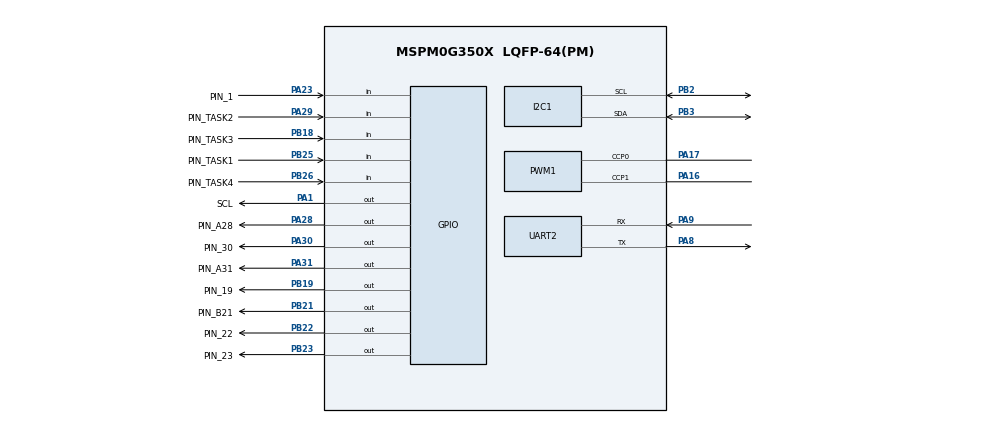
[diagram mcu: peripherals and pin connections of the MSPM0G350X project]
/**
 * @cliArgs --device "MSPM0G350X" --part "Default" --package "LQFP-64(PM)" --product "mspm0_sdk@2.05.01.00"
 * @versions {"tool":"1.24.0+4150"}
 */

/**
 * Import the modules used in this configuration.
 */
const GPIO    = scripting.addModule("/ti/driverlib/GPIO", {}, false);
const GPIO1   = GPIO.addInstance();
const GPIO2   = GPIO.addInstance();
const GPIO3   = GPIO.addInstance();
const GPIO4   = GPIO.addInstance();
const GPIO5   = GPIO.addInstance();
const GPIO6   = GPIO.addInstance();
const GPIO7   = GPIO.addInstance();
const GPIO8   = GPIO.addInstance();
const I2C     = scripting.addModule("/ti/driverlib/I2C", {}, false);
const I2C1    = I2C.addInstance();
const PWM     = scripting.addModule("/ti/driverlib/PWM", {}, false);
const PWM1    = PWM.addInstance();
const SYSCTL  = scripting.addModule("/ti/driverlib/SYSCTL");
const SYSTICK = scripting.addModule("/ti/driverlib/SYSTICK");
const TIMER   = scripting.addModule("/ti/driverlib/TIMER", {}, false);
const TIMER1  = TIMER.addInstance();
const TIMER2  = TIMER.addInstance();
const UART    = scripting.addModule("/ti/driverlib/UART", {}, false);
const UART1   = UART.addInstance();
const UART2   = UART.addInstance();
const UART3   = UART.addInstance();

/**
 * Write custom configuration values to the imported modules.
 */
const gate7  = system.clockTree["MFCLKGATE"];
gate7.enable = true;

GPIO1.$name                   = "GPIO_GRP_0";
GPIO1.associatedPins[0].$name = "PIN_0";

const Board = scripting.addModule("/ti/driverlib/Board", {}, false);

GPIO2.$name                   = "OLED";
GPIO2.associatedPins.create(3);
GPIO2.associatedPins[0].$name = "RES";
GPIO2.associatedPins[1].$name = "DC";
GPIO2.associatedPins[2].$name = "CS";

GPIO3.$name                               = "GPIO_ENCODER";
GPIO3.port                                = "PORTA";
GPIO3.associatedPins.create(2);
GPIO3.associatedPins[0].$name             = "PIN_LA";
GPIO3.associatedPins[0].direction         = "INPUT";
GPIO3.associatedPins[0].interruptEn       = true;
GPIO3.associatedPins[0].polarity          = "RISE";
GPIO3.associatedPins[0].assignedPin       = "26";
GPIO3.associatedPins[0].interruptPriority = "1";
GPIO3.associatedPins[1].direction         = "INPUT";
GPIO3.associatedPins[1].interruptEn       = true;
GPIO3.associatedPins[1].polarity          = "RISE";
GPIO3.associatedPins[1].assignedPin       = "27";
GPIO3.associatedPins[1].$name             = "PIN_LB";
GPIO3.associatedPins[1].interruptPriority = "1";

GPIO4.$name                          = "GPIO_MOTOR";
GPIO4.port                           = "PORTA";
GPIO4.associatedPins.create(4);
GPIO4.associatedPins[0].assignedPin  = "14";
GPIO4.associatedPins[0].$name        = "PIN_A14";
GPIO4.associatedPins[1].initialValue = "SET";
GPIO4.associatedPins[1].assignedPin  = "15";
GPIO4.associatedPins[1].$name        = "PIN_A15";
GPIO4.associatedPins[2].initialValue = "SET";
GPIO4.associatedPins[2].$name        = "PIN_A28";
GPIO4.associatedPins[2].assignedPin  = "28";
GPIO4.associatedPins[2].pin.$assign  = "PA28";
GPIO4.associatedPins[3].$name        = "PIN_A31";
GPIO4.associatedPins[3].assignedPin  = "31";
GPIO4.associatedPins[3].pin.$assign  = "PA31";

GPIO5.$name                               = "GPIO_BUTTON";
GPIO5.associatedPins.create(4);
GPIO5.associatedPins[0].direction         = "INPUT";
GPIO5.associatedPins[0].internalResistor  = "PULL_UP";
GPIO5.associatedPins[0].assignedPin       = "25";
GPIO5.associatedPins[0].$name             = "PIN_TASK1";
GPIO5.associatedPins[0].interruptEn       = true;
GPIO5.associatedPins[0].polarity          = "FALL";
GPIO5.associatedPins[0].assignedPort      = "PORTB";
GPIO5.associatedPins[0].pin.$assign       = "PB25";
GPIO5.associatedPins[1].direction         = "INPUT";
GPIO5.associatedPins[1].internalResistor  = "PULL_UP";
GPIO5.associatedPins[1].assignedPort      = "PORTA";
GPIO5.associatedPins[1].assignedPin       = "29";
GPIO5.associatedPins[1].$name             = "PIN_TASK2";
GPIO5.associatedPins[1].interruptEn       = true;
GPIO5.associatedPins[1].polarity          = "FALL";
GPIO5.associatedPins[1].pin.$assign       = "PA29";
GPIO5.associatedPins[2].direction         = "INPUT";
GPIO5.associatedPins[2].internalResistor  = "PULL_UP";
GPIO5.associatedPins[2].assignedPort      = "PORTB";
GPIO5.associatedPins[2].$name             = "PIN_TASK3";
GPIO5.associatedPins[2].interruptEn       = true;
GPIO5.associatedPins[2].polarity          = "FALL";
GPIO5.associatedPins[2].interruptPriority = "0";
GPIO5.associatedPins[2].assignedPin       = "18";
GPIO5.associatedPins[2].pin.$assign       = "PB18";
GPIO5.associatedPins[3].direction         = "INPUT";
GPIO5.associatedPins[3].assignedPort      = "PORTB";
GPIO5.associatedPins[3].internalResistor  = "PULL_UP";
GPIO5.associatedPins[3].$name             = "PIN_TASK4";
GPIO5.associatedPins[3].interruptPriority = "0";
GPIO5.associatedPins[3].polarity          = "FALL";
GPIO5.associatedPins[3].interruptEn       = true;
GPIO5.associatedPins[3].assignedPin       = "26";
GPIO5.associatedPins[3].pin.$assign       = "PB26";

GPIO6.$name                          = "IIC_Software";
GPIO6.port                           = "PORTA";
GPIO6.associatedPins.create(2);
GPIO6.associatedPins[0].$name        = "SCL";
GPIO6.associatedPins[0].initialValue = "SET";
GPIO6.associatedPins[0].ioStructure  = "OD";
GPIO6.associatedPins[0].assignedPin  = "1";
GPIO6.associatedPins[0].pin.$assign  = "PA1";
GPIO6.associatedPins[1].$name        = "SDA";
GPIO6.associatedPins[1].initialValue = "SET";
GPIO6.associatedPins[1].ioStructure  = "OD";
GPIO6.associatedPins[1].assignedPin  = "0";

GPIO7.$name                              = "TRACK";
GPIO7.associatedPins.create(5);
GPIO7.associatedPins[0].$name            = "PIN_1";
GPIO7.associatedPins[0].direction        = "INPUT";
GPIO7.associatedPins[0].internalResistor = "PULL_UP";
GPIO7.associatedPins[0].assignedPin      = "23";
GPIO7.associatedPins[0].assignedPort     = "PORTA";
GPIO7.associatedPins[0].pin.$assign      = "PA23";
GPIO7.associatedPins[1].$name            = "PIN_2";
GPIO7.associatedPins[1].direction        = "INPUT";
GPIO7.associatedPins[1].assignedPin      = "24";
GPIO7.associatedPins[1].internalResistor = "PULL_UP";
GPIO7.associatedPins[2].$name            = "PIN_3";
GPIO7.associatedPins[2].direction        = "INPUT";
GPIO7.associatedPins[2].assignedPin      = "10";
GPIO7.associatedPins[2].internalResistor = "PULL_UP";
GPIO7.associatedPins[3].$name            = "PIN_4";
GPIO7.associatedPins[3].assignedPin      = "13";
GPIO7.associatedPins[3].direction        = "INPUT";
GPIO7.associatedPins[3].internalResistor = "PULL_UP";
GPIO7.associatedPins[4].$name            = "PIN_5";
GPIO7.associatedPins[4].assignedPin      = "12";
GPIO7.associatedPins[4].direction        = "INPUT";
GPIO7.associatedPins[4].internalResistor = "PULL_UP";

GPIO8.$name                                       = "YUNTAI";
GPIO8.associatedPins.create(6);
GPIO8.associatedPins[0].$name                     = "PIN_19";
GPIO8.associatedPins[0].assignedPort              = "PORTB";
GPIO8.associatedPins[0].assignedPin               = "19";
GPIO8.associatedPins[0].pin.$assign               = "PB19";
GPIO8.associatedPins[1].$name                     = "PIN_21";
GPIO8.associatedPins[1].assignedPort              = "PORTA";
GPIO8.associatedPins[1].assignedPin               = "21";
GPIO8.associatedPins[1].pin.$assignAllowConflicts = "PA21";
GPIO8.associatedPins[2].$name                     = "PIN_B21";
GPIO8.associatedPins[2].assignedPort              = "PORTB";
GPIO8.associatedPins[2].assignedPin               = "21";
GPIO8.associatedPins[2].pin.$assign               = "PB21";
GPIO8.associatedPins[3].$name                     = "PIN_22";
GPIO8.associatedPins[3].pin.$assign               = "PB22";
GPIO8.associatedPins[4].assignedPort              = "PORTA";
GPIO8.associatedPins[4].$name                     = "PIN_30";
GPIO8.associatedPins[4].pin.$assign               = "PA30";
GPIO8.associatedPins[5].$name                     = "PIN_23";
GPIO8.associatedPins[5].assignedPort              = "PORTB";
GPIO8.associatedPins[5].pin.$assign               = "PB23";

I2C1.$name                             = "I2C_OLED";
I2C1.basicEnableController             = true;
I2C1.basicClockSourceDivider           = 4;
I2C1.peripheral.sdaPin.$assign         = "PB3";
I2C1.peripheral.sclPin.$assign         = "PB2";
I2C1.sdaPinConfig.hideOutputInversion  = scripting.forceWrite(false);
I2C1.sdaPinConfig.onlyInternalResistor = scripting.forceWrite(false);
I2C1.sdaPinConfig.passedPeripheralType = scripting.forceWrite("Digital");
I2C1.sdaPinConfig.$name                = "ti_driverlib_gpio_GPIOPinGeneric2";
I2C1.sclPinConfig.hideOutputInversion  = scripting.forceWrite(false);
I2C1.sclPinConfig.onlyInternalResistor = scripting.forceWrite(false);
I2C1.sclPinConfig.passedPeripheralType = scripting.forceWrite("Digital");
I2C1.sclPinConfig.$name                = "ti_driverlib_gpio_GPIOPinGeneric3";

PWM1.clockDivider                       = 8;
PWM1.timerStartTimer                    = true;
PWM1.$name                              = "PWM_1";
PWM1.pwmMode                            = "EDGE_ALIGN_UP";
PWM1.peripheral.ccp0Pin.$assign         = "PA17";
PWM1.peripheral.ccp1Pin.$assign         = "PA16";
PWM1.PWM_CHANNEL_0.$name                = "ti_driverlib_pwm_PWMTimerCC0";
PWM1.PWM_CHANNEL_1.$name                = "ti_driverlib_pwm_PWMTimerCC1";
PWM1.ccp0PinConfig.direction            = scripting.forceWrite("OUTPUT");
PWM1.ccp0PinConfig.hideOutputInversion  = scripting.forceWrite(false);
PWM1.ccp0PinConfig.onlyInternalResistor = scripting.forceWrite(false);
PWM1.ccp0PinConfig.passedPeripheralType = scripting.forceWrite("Digital");
PWM1.ccp0PinConfig.$name                = "ti_driverlib_gpio_GPIOPinGeneric0";
PWM1.ccp1PinConfig.direction            = scripting.forceWrite("OUTPUT");
PWM1.ccp1PinConfig.hideOutputInversion  = scripting.forceWrite(false);
PWM1.ccp1PinConfig.onlyInternalResistor = scripting.forceWrite(false);
PWM1.ccp1PinConfig.passedPeripheralType = scripting.forceWrite("Digital");
PWM1.ccp1PinConfig.$name                = "ti_driverlib_gpio_GPIOPinGeneric1";

SYSCTL.forceDefaultClkConfig = true;
SYSCTL.clockTreeEn           = true;

SYSTICK.periodEnable      = true;
SYSTICK.period            = 32000;
SYSTICK.interruptEnable   = true;
SYSTICK.interruptPriority = "0";
SYSTICK.systickEnable     = true;

TIMER1.$name              = "TIMER_TICK";
TIMER1.timerClkDiv        = 8;
TIMER1.timerMode          = "PERIODIC";
TIMER1.timerStartTimer    = true;
TIMER1.interrupts         = ["ZERO"];
TIMER1.timerClkPrescale   = 100;
TIMER1.timerPeriod        = "30ms";
TIMER1.peripheral.$assign = "TIMG0";

TIMER2.$name              = "TIMER_0";
TIMER2.interrupts         = ["ZERO"];
TIMER2.timerMode          = "PERIODIC";
TIMER2.timerStartTimer    = true;
TIMER2.timerPeriod        = "0.5 ms";
TIMER2.peripheral.$assign = "TIMA0";

UART1.$name              = "UART_0";
UART1.uartClkSrc         = "MFCLK";
UART1.enabledInterrupts  = ["RX"];
UART1.targetBaudRate     = 115200;
UART1.peripheral.$assign = "UART0";
UART1.txPinConfig.$name  = "ti_driverlib_gpio_GPIOPinGeneric4";
UART1.rxPinConfig.$name  = "ti_driverlib_gpio_GPIOPinGeneric5";

UART2.$name                    = "UART_1";
UART2.uartClkSrc               = "MFCLK";
UART2.targetBaudRate           = 115200;
UART2.enabledInterrupts        = ["RX"];
UART2.peripheral.$assign       = "UART1";
UART2.peripheral.rxPin.$assign = "PA9";
UART2.peripheral.txPin.$assign = "PA8";
UART2.txPinConfig.$name        = "ti_driverlib_gpio_GPIOPinGeneric8";
UART2.rxPinConfig.$name        = "ti_driverlib_gpio_GPIOPinGeneric9";

UART3.$name             = "UART_2";
UART3.txPinConfig.$name = "ti_driverlib_gpio_GPIOPinGeneric10";
UART3.rxPinConfig.$name = "ti_driverlib_gpio_GPIOPinGeneric11";

/**
 * Pinmux solution for unlocked pins/peripherals. This ensures that minor changes to the automatic solver in a future
 * version of the tool will not impact the pinmux you originally saw.  These lines can be completely deleted in order to
 * re-solve from scratch.
 */
GPIO1.associatedPins[0].pin.$suggestSolution = "PB14";
Board.peripheral.$suggestSolution            = "DEBUGSS";
Board.peripheral.swclkPin.$suggestSolution   = "PA20";
Board.peripheral.swdioPin.$suggestSolution   = "PA19";
GPIO2.associatedPins[0].pin.$suggestSolution = "PB16";
GPIO2.associatedPins[1].pin.$suggestSolution = "PA13";
GPIO2.associatedPins[2].pin.$suggestSolution = "PA18";
GPIO3.associatedPins[0].pin.$suggestSolution = "PA26";
GPIO3.associatedPins[1].pin.$suggestSolution = "PA27";
GPIO4.associatedPins[0].pin.$suggestSolution = "PA14";
GPIO4.associatedPins[1].pin.$suggestSolution = "PA15";
GPIO6.associatedPins[1].pin.$suggestSolution = "PA0";
GPIO7.associatedPins[1].pin.$suggestSolution = "PB24";
GPIO7.associatedPins[2].pin.$suggestSolution = "PB10";
GPIO7.associatedPins[3].pin.$suggestSolution = "PB13";
GPIO7.associatedPins[4].pin.$suggestSolution = "PA12";
I2C1.peripheral.$suggestSolution             = "I2C1";
PWM1.peripheral.$suggestSolution             = "TIMA1";
UART1.peripheral.rxPin.$suggestSolution      = "PA11";
UART1.peripheral.txPin.$suggestSolution      = "PA10";
UART3.peripheral.$suggestSolution            = "UART2";
UART3.peripheral.rxPin.$suggestSolution      = "PA22";
UART3.peripheral.txPin.$suggestSolution      = "PB15";
